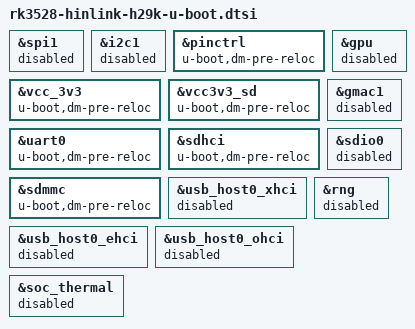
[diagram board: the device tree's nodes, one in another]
// SPDX-License-Identifier: (GPL-2.0+ OR MIT)

#include "rk3528-u-boot.dtsi"

&spi1 {
    status = "disabled";
};

&i2c1 {
    status = "disabled";
};

&pinctrl {
    u-boot,dm-pre-reloc;
};

&vcc_3v3 {
    u-boot,dm-pre-reloc;
};

&vcc3v3_sd {
    u-boot,dm-pre-reloc;
};

&uart0 {
    u-boot,dm-pre-reloc;
};

&sdhci {
    u-boot,dm-pre-reloc;
};

&sdmmc {
    u-boot,dm-pre-reloc;
};

&gpu {
    status = "disabled";
};

&gmac1 {
    status = "disabled";
};

&usb_host0_xhci {
    status = "disabled";
};

&usb_host0_ehci {
    status = "disabled";
};

&usb_host0_ohci {
    status = "disabled";
};

&sdio0 {
    status = "disabled";
};

&soc_thermal {
    status = "disabled";
};

&rng {
    status = "disabled";
};
